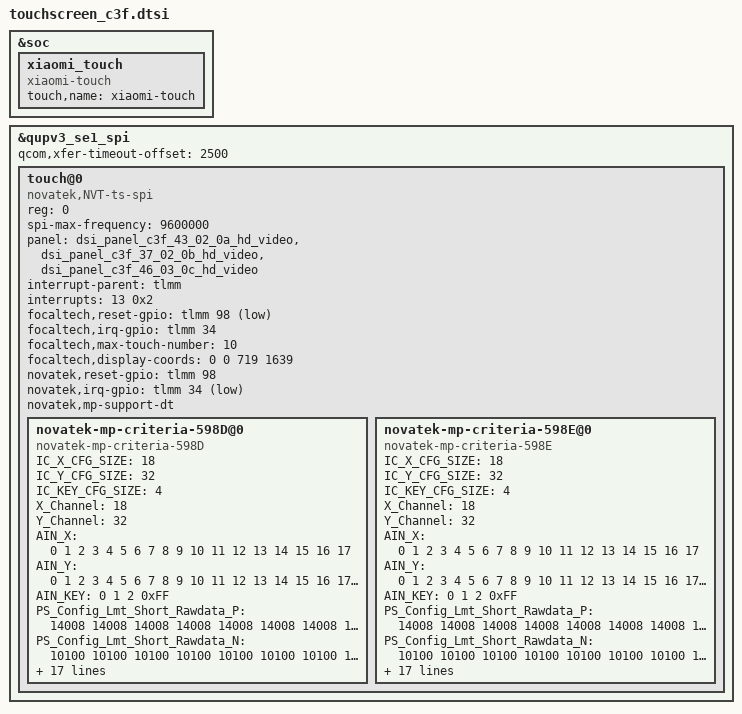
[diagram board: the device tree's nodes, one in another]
/*
 * Copyright (C) 2024 Novatek, Inc.
 *
 * $Revision$
 * $Date$
 *
 * This program is free software; you can redistribute it and/or modify
 * it under the terms of the GNU General Public License as published by
 * the Free Software Foundation; either version 2 of the License, or
 * (at your option) any later version.
 *
 * This program is distributed in the hope that it will be useful, but WITHOUT
 * ANY WARRANTY; without even the implied warranty of MERCHANTABILITY or
 * FITNESS FOR A PARTICULAR PURPOSE.  See the GNU General Public License for
 * more details.
 *
 */
&soc {
    xiaomi_touch {
        status = "okay";
        compatible = "xiaomi-touch";
        touch,name = "xiaomi-touch";
    };
};

&qupv3_se1_spi {
    status = "ok";
    qcom,xfer-timeout-offset = <2500>;

    touch@0 {
        compatible = "novatek,NVT-ts-spi","focaltech,fts";
        reg = <0>; //Same as CS ID
        status = "ok";

        spi-max-frequency = <9600000>;    //4800000,9600000,15000000,19200000
        panel = <&dsi_panel_c3f_43_02_0a_hd_video &dsi_panel_c3f_37_02_0b_hd_video &dsi_panel_c3f_46_03_0c_hd_video>;

        /*************** Focaltech FT8057M device tree ***************/
        interrupt-parent = <&tlmm>;
        interrupts = <13 0x2>;
        focaltech,reset-gpio = <&tlmm 98 0x01>;
        focaltech,irq-gpio = <&tlmm 34 0x02>;
        focaltech,max-touch-number = <10>;
        focaltech,display-coords =  <0 0 719 1639>;

        /*************** Novatek NT36528 device tree ***************/
        novatek,reset-gpio = <&tlmm 98 0x00>;
        novatek,irq-gpio = <&tlmm 34 0x2001>;

        //novatek,pen-support;
        //novatek,spi-rd-fast-addr = <0x03F310>;

        /* MP */
        novatek,mp-support-dt;

        /* for Xiaomi C3F NT36528A Truly 6.88" panel module */
        novatek-mp-criteria-598D@0 {
            #address-cells = <1>;
            #size-cells = <0>;
            compatible = "novatek-mp-criteria-598D";

            /* MP Config */
            IC_X_CFG_SIZE = <18>;
            IC_Y_CFG_SIZE = <32>;
            IC_KEY_CFG_SIZE = <4>;
            X_Channel = <18>;
            Y_Channel = <32>;
            AIN_X = <0 1 2 3 4 5 6 7 8 9 10 11 12 13 14 15 16 17>;
            AIN_Y = <0 1 2 3 4 5 6 7 8 9 10 11 12 13 14 15 16 17 18 19 20 21 22 23 24 25 26 27 28 29 30 31>;
            AIN_KEY = <0 1 2 0xFF>;

            /* MP Criteria */
            PS_Config_Lmt_Short_Rawdata_P = <
                14008 14008 14008 14008 14008 14008 14008 14008 14008 14008 14008 14008 14008 14008 14008 14008 14008 14008
                14008 14008 14008 14008 14008 14008 14008 14008 14008 14008 14008 14008 14008 14008 14008 14008 14008 14008
                14008 14008 14008 14008 14008 14008 14008 14008 14008 14008 14008 14008 14008 14008 14008 14008 14008 14008
                14008 14008 14008 14008 14008 14008 14008 14008 14008 14008 14008 14008 14008 14008 14008 14008 14008 14008
                14008 14008 14008 14008 14008 14008 14008 14008 14008 14008 14008 14008 14008 14008 14008 14008 14008 14008
                14008 14008 14008 14008 14008 14008 14008 14008 14008 14008 14008 14008 14008 14008 14008 14008 14008 14008
                14008 14008 14008 14008 14008 14008 14008 14008 14008 14008 14008 14008 14008 14008 14008 14008 14008 14008
                14008 14008 14008 14008 14008 14008 14008 14008 14008 14008 14008 14008 14008 14008 14008 14008 14008 14008
                14008 14008 14008 14008 14008 14008 14008 14008 14008 14008 14008 14008 14008 14008 14008 14008 14008 14008
                14008 14008 14008 14008 14008 14008 14008 14008 14008 14008 14008 14008 14008 14008 14008 14008 14008 14008
                14008 14008 14008 14008 14008 14008 14008 14008 14008 14008 14008 14008 14008 14008 14008 14008 14008 14008
                14008 14008 14008 14008 14008 14008 14008 14008 14008 14008 14008 14008 14008 14008 14008 14008 14008 14008
                14008 14008 14008 14008 14008 14008 14008 14008 14008 14008 14008 14008 14008 14008 14008 14008 14008 14008
                14008 14008 14008 14008 14008 14008 14008 14008 14008 14008 14008 14008 14008 14008 14008 14008 14008 14008
                14008 14008 14008 14008 14008 14008 14008 14008 14008 14008 14008 14008 14008 14008 14008 14008 14008 14008
                14008 14008 14008 14008 14008 14008 14008 14008 14008 14008 14008 14008 14008 14008 14008 14008 14008 14008
                14008 14008 14008 14008 14008 14008 14008 14008 14008 14008 14008 14008 14008 14008 14008 14008 14008 14008
                14008 14008 14008 14008 14008 14008 14008 14008 14008 14008 14008 14008 14008 14008 14008 14008 14008 14008
                14008 14008 14008 14008 14008 14008 14008 14008 14008 14008 14008 14008 14008 14008 14008 14008 14008 14008
                14008 14008 14008 14008 14008 14008 14008 14008 14008 14008 14008 14008 14008 14008 14008 14008 14008 14008
                14008 14008 14008 14008 14008 14008 14008 14008 14008 14008 14008 14008 14008 14008 14008 14008 14008 14008
                14008 14008 14008 14008 14008 14008 14008 14008 14008 14008 14008 14008 14008 14008 14008 14008 14008 14008
                14008 14008 14008 14008 14008 14008 14008 14008 14008 14008 14008 14008 14008 14008 14008 14008 14008 14008
                14008 14008 14008 14008 14008 14008 14008 14008 14008 14008 14008 14008 14008 14008 14008 14008 14008 14008
                14008 14008 14008 14008 14008 14008 14008 14008 14008 14008 14008 14008 14008 14008 14008 14008 14008 14008
                14008 14008 14008 14008 14008 14008 14008 14008 14008 14008 14008 14008 14008 14008 14008 14008 14008 14008
                14008 14008 14008 14008 14008 14008 14008 14008 14008 14008 14008 14008 14008 14008 14008 14008 14008 14008
                14008 14008 14008 14008 14008 14008 14008 14008 14008 14008 14008 14008 14008 14008 14008 14008 14008 14008
                14008 14008 14008 14008 14008 14008 14008 14008 14008 14008 14008 14008 14008 14008 14008 14008 14008 14008
                14008 14008 14008 14008 14008 14008 14008 14008 14008 14008 14008 14008 14008 14008 14008 14008 14008 14008
                14008 14008 14008 14008 14008 14008 14008 14008 14008 14008 14008 14008 14008 14008 14008 14008 14008 14008
                14008 14008 14008 14008 14008 14008 14008 14008 14008 14008 14008 14008 14008 14008 14008 14008 14008 14008
                14008 14008 14008>;

            PS_Config_Lmt_Short_Rawdata_N = <
                10100 10100 10100 10100 10100 10100 10100 10100 10100 10100 10100 10100 10100 10100 10100 10100 10100 10100
                10100 10100 10100 10100 10100 10100 10100 10100 10100 10100 10100 10100 10100 10100 10100 10100 10100 10100
                10100 10100 10100 10100 10100 10100 10100 10100 10100 10100 10100 10100 10100 10100 10100 10100 10100 10100
                10100 10100 10100 10100 10100 10100 10100 10100 10100 10100 10100 10100 10100 10100 10100 10100 10100 10100
                10100 10100 10100 10100 10100 10100 10100 10100 10100 10100 10100 10100 10100 10100 10100 10100 10100 10100
                10100 10100 10100 10100 10100 10100 10100 10100 10100 10100 10100 10100 10100 10100 10100 10100 10100 10100
                10100 10100 10100 10100 10100 10100 10100 10100 10100 10100 10100 10100 10100 10100 10100 10100 10100 10100
                10100 10100 10100 10100 10100 10100 10100 10100 10100 10100 10100 10100 10100 10100 10100 10100 10100 10100
                10100 10100 10100 10100 10100 10100 10100 10100 10100 10100 10100 10100 10100 10100 10100 10100 10100 10100
                10100 10100 10100 10100 10100 10100 10100 10100 10100 10100 10100 10100 10100 10100 10100 10100 10100 10100
                10100 10100 10100 10100 10100 10100 10100 10100 10100 10100 10100 10100 10100 10100 10100 10100 10100 10100
                10100 10100 10100 10100 10100 10100 10100 10100 10100 10100 10100 10100 10100 10100 10100 10100 10100 10100
                10100 10100 10100 10100 10100 10100 10100 10100 10100 10100 10100 10100 10100 10100 10100 10100 10100 10100
                10100 10100 10100 10100 10100 10100 10100 10100 10100 10100 10100 10100 10100 10100 10100 10100 10100 10100
                10100 10100 10100 10100 10100 10100 10100 10100 10100 10100 10100 10100 10100 10100 10100 10100 10100 10100
                10100 10100 10100 10100 10100 10100 10100 10100 10100 10100 10100 10100 10100 10100 10100 10100 10100 10100
                10100 10100 10100 10100 10100 10100 10100 10100 10100 10100 10100 10100 10100 10100 10100 10100 10100 10100
                10100 10100 10100 10100 10100 10100 10100 10100 10100 10100 10100 10100 10100 10100 10100 10100 10100 10100
                10100 10100 10100 10100 10100 10100 10100 10100 10100 10100 10100 10100 10100 10100 10100 10100 10100 10100
                10100 10100 10100 10100 10100 10100 10100 10100 10100 10100 10100 10100 10100 10100 10100 10100 10100 10100
                10100 10100 10100 10100 10100 10100 10100 10100 10100 10100 10100 10100 10100 10100 10100 10100 10100 10100
                10100 10100 10100 10100 10100 10100 10100 10100 10100 10100 10100 10100 10100 10100 10100 10100 10100 10100
                10100 10100 10100 10100 10100 10100 10100 10100 10100 10100 10100 10100 10100 10100 10100 10100 10100 10100
                10100 10100 10100 10100 10100 10100 10100 10100 10100 10100 10100 10100 10100 10100 10100 10100 10100 10100
                10100 10100 10100 10100 10100 10100 10100 10100 10100 10100 10100 10100 10100 10100 10100 10100 10100 10100
                10100 10100 10100 10100 10100 10100 10100 10100 10100 10100 10100 10100 10100 10100 10100 10100 10100 10100
                10100 10100 10100 10100 10100 10100 10100 10100 10100 10100 10100 10100 10100 10100 10100 10100 10100 10100
                10100 10100 10100 10100 10100 10100 10100 10100 10100 10100 10100 10100 10100 10100 10100 10100 10100 10100
                10100 10100 10100 10100 10100 10100 10100 10100 10100 10100 10100 10100 10100 10100 10100 10100 10100 10100
                10100 10100 10100 10100 10100 10100 10100 10100 10100 10100 10100 10100 10100 10100 10100 10100 10100 10100
                10100 10100 10100 10100 10100 10100 10100 10100 10100 10100 10100 10100 10100 10100 10100 10100 10100 10100
                10100 10100 10100 10100 10100 10100 10100 10100 10100 10100 10100 10100 10100 10100 10100 10100 10100 10100
                10000 10000 10000>;

            PS_Config_Lmt_Open_Rawdata_P = <
                2594 2575 2547 2524 2500 2492 2503 2444 65535 65535 2391 2437 2428 2422 2418 2421 2443 2514
                2673 2667 2647 2643 2631 2617 2615 2597 2580 2456 2471 2479 2477 2474 2463 2453 2468 2533
                2712 2712 2694 2688 2680 2664 2657 2638 2621 2509 2523 2531 2530 2524 2510 2496 2510 2573
                2661 2675 2654 2649 2638 2626 2619 2601 2580 2533 2549 2559 2556 2547 2535 2526 2540 2603
                2727 2754 2737 2729 2723 2709 2701 2688 2664 2561 2570 2580 2576 2580 2563 2547 2561 2617
                2808 2843 2824 2817 2810 2796 2792 2772 2754 2583 2598 2611 2611 2608 2594 2582 2601 2653
                2757 2701 2654 2646 2628 2610 2617 2603 2590 2654 2663 2667 2654 2652 2653 2649 2692 2650
                2797 2730 2688 2675 2657 2642 2652 2640 2626 2705 2717 2716 2702 2702 2702 2701 2737 2709
                2849 2778 2740 2724 2710 2698 2712 2699 2682 2734 2738 2747 2726 2723 2717 2713 2750 2738
                2888 2815 2778 2762 2741 2733 2745 2734 2722 2743 2752 2762 2747 2743 2740 2734 2769 2769
                2919 2846 2806 2793 2776 2766 2779 2766 2751 2862 2874 2870 2856 2853 2850 2849 2888 2892
                2971 2894 2856 2845 2821 2815 2827 2813 2797 2871 2883 2885 2866 2864 2860 2853 2891 2909
                3024 2947 2909 2899 2877 2867 2887 2869 2859 2887 2905 2899 2880 2870 2862 2855 2895 2926
                3066 2988 2947 2939 2922 2913 2922 2909 2894 2902 2920 2922 2909 2908 2897 2890 2922 2958
                3112 3032 2992 2982 2972 2962 2975 2962 2941 3020 3034 3044 3024 3020 3014 3000 3032 3083
                3184 3107 3073 3060 3045 3035 3042 3031 3010 2999 3013 3017 3003 2996 2993 2986 3020 3077
                3259 3175 3139 3129 3115 3098 3109 3097 3079 3088 3098 3104 3090 3093 3081 3065 3097 3172
                3266 3185 3156 3143 3128 3119 3128 3107 3088 3077 3087 3097 3077 3073 3072 3063 3091 3163
                3315 3238 3206 3200 3181 3171 3182 3160 3147 3142 3158 3160 3157 3147 3139 3132 3161 3234
                3340 3261 3230 3224 3212 3202 3213 3196 3174 3158 3178 3178 3167 3157 3153 3147 3178 3259
                3461 3387 3352 3349 3335 3325 3333 3318 3293 3221 3242 3252 3242 3228 3223 3209 3240 3321
                3499 3422 3389 3380 3368 3356 3364 3346 3318 3290 3312 3319 3314 3314 3307 3297 3321 3401
                3541 3459 3429 3420 3412 3402 3408 3395 3366 3354 3374 3385 3377 3377 3374 3360 3385 3464
                3587 3506 3479 3465 3457 3447 3444 3429 3401 3381 3401 3408 3398 3395 3385 3374 3401 3475
                3737 3655 3629 3619 3597 3585 3592 3577 3550 3508 3534 3539 3528 3524 3514 3506 3529 3611
                3686 3618 3592 3581 3562 3553 3556 3535 3507 3508 3532 3542 3535 3541 3536 3528 3549 3625
                3762 3692 3662 3655 3646 3632 3634 3612 3584 3550 3580 3584 3574 3566 3555 3545 3569 3644
                3800 3728 3703 3696 3679 3674 3678 3655 3630 3564 3588 3601 3592 3590 3588 3576 3592 3671
                3697 3828 3801 3797 3786 3776 3773 3752 3723 3651 3679 3692 3679 3681 3678 3661 3681 3583
                3742 3863 3844 3832 3816 3802 3797 3772 3742 3676 3702 3713 3710 3716 3710 3699 3711 3632
                3794 3947 3923 3912 3891 3881 3881 3863 3830 3721 3745 3753 3748 3753 3742 3738 3758 3654
                3802 3966 3976 3962 3940 3917 3913 3896 3872 3742 3765 3774 3774 3776 3772 3767 3753 3643
                5120 5120 5120>;

            PS_Config_Lmt_Open_Rawdata_N = <
                1112 1103 1091 1082 1072 1068 1073 1048 (-65535) (-65535) 1025 1045 1040 1038 1036 1037 1047 1078
                1145 1143 1135 1133 1127 1121 1121 1113 1106 1052 1059 1063 1061 1060 1055 1051 1058 1085
                1162 1162 1154 1152 1148 1142 1139 1130 1123 1075 1081 1085 1084 1082 1076 1070 1076 1103
                1141 1147 1138 1135 1130 1126 1123 1115 1106 1085 1093 1097 1096 1091 1087 1082 1088 1115
                1169 1180 1173 1169 1167 1161 1157 1152 1142 1097 1102 1106 1104 1106 1099 1091 1097 1121
                1204 1219 1210 1207 1204 1198 1196 1188 1180 1107 1114 1119 1119 1118 1112 1106 1115 1137
                1181 1157 1138 1134 1126 1118 1121 1115 1110 1138 1141 1143 1138 1136 1137 1135 1154 1136
                1199 1170 1152 1147 1139 1132 1136 1132 1126 1159 1165 1164 1158 1158 1158 1157 1173 1161
                1221 1190 1174 1168 1162 1156 1162 1157 1150 1172 1174 1177 1168 1167 1165 1163 1178 1174
                1238 1207 1190 1184 1175 1171 1177 1172 1166 1175 1180 1184 1177 1175 1174 1172 1187 1187
                1251 1220 1202 1197 1190 1186 1191 1186 1179 1226 1232 1230 1224 1223 1222 1221 1238 1240
                1273 1240 1224 1219 1209 1207 1211 1205 1199 1231 1235 1237 1228 1228 1226 1223 1239 1247
                1296 1263 1247 1243 1233 1229 1237 1229 1225 1237 1245 1243 1234 1230 1226 1223 1241 1254
                1314 1280 1263 1259 1252 1249 1252 1247 1240 1244 1252 1252 1247 1246 1241 1238 1252 1268
                1334 1300 1282 1278 1274 1270 1275 1270 1261 1294 1300 1304 1296 1294 1292 1286 1300 1321
                1364 1331 1317 1312 1305 1301 1304 1299 1290 1285 1291 1293 1287 1284 1283 1280 1294 1319
                1397 1361 1345 1341 1335 1328 1333 1327 1319 1324 1328 1330 1324 1325 1321 1313 1327 1360
                1400 1365 1352 1347 1340 1337 1340 1331 1324 1319 1323 1327 1319 1317 1316 1313 1325 1355
                1421 1388 1374 1372 1363 1359 1364 1354 1349 1346 1354 1354 1353 1349 1345 1342 1355 1386
                1432 1397 1384 1382 1376 1372 1377 1370 1360 1354 1362 1362 1357 1353 1351 1349 1362 1397
                1483 1451 1436 1435 1429 1425 1429 1422 1411 1381 1390 1394 1390 1384 1381 1375 1388 1423
                1499 1466 1453 1448 1444 1438 1442 1434 1422 1410 1420 1423 1420 1420 1417 1413 1423 1457
                1517 1483 1469 1466 1462 1458 1460 1455 1442 1438 1446 1451 1447 1447 1446 1440 1451 1484
                1537 1502 1491 1485 1481 1477 1476 1469 1457 1449 1457 1460 1456 1455 1451 1446 1457 1489
                1601 1567 1555 1551 1541 1537 1540 1533 1522 1504 1514 1517 1512 1510 1506 1502 1513 1547
                1580 1550 1540 1535 1526 1523 1524 1515 1503 1504 1514 1518 1515 1517 1516 1512 1521 1553
                1612 1582 1570 1567 1562 1556 1558 1548 1536 1522 1534 1536 1532 1528 1523 1519 1529 1562
                1628 1598 1587 1584 1577 1574 1576 1567 1556 1528 1538 1543 1540 1538 1538 1532 1540 1573
                1585 1640 1629 1627 1622 1618 1617 1608 1595 1565 1577 1582 1577 1577 1576 1569 1577 1535
                1604 1655 1648 1642 1636 1630 1627 1616 1604 1576 1586 1591 1590 1592 1590 1585 1591 1556
                1626 1691 1681 1676 1667 1663 1663 1655 1642 1595 1605 1609 1606 1609 1604 1602 1610 1566
                1630 1700 1704 1698 1688 1679 1677 1670 1660 1604 1613 1618 1618 1618 1616 1615 1609 1561
                (-511) (-511) (-511)>;

            PS_Config_Lmt_FW_Rawdata_P = <
                1124 1102 1133 1105 1096 1110 1131 1114 65535 65535 1112 1121 1119 1109 1106 1124 1126 1113
                1117 1110 1119 1117 1113 1114 1113 1112 1133 1130 1124 1126 1131 1128 1127 1114 1117 1123
                1133 1103 1102 1135 1137 1130 1126 1123 1130 1121 1127 1121 1119 1123 1119 1116 1119 1127
                1135 1102 1114 1127 1123 1126 1124 1127 1120 1113 1134 1137 1134 1131 1130 1113 1126 1109
                1117 1116 1121 1109 1100 1106 1105 1109 1123 1121 1116 1114 1114 1110 1105 1130 1119 1120
                1130 1112 1128 1114 1113 1113 1103 1102 1135 1107 1123 1120 1120 1126 1121 1116 1112 1120
                1119 1116 1119 1121 1112 1116 1114 1102 1100 1113 1114 1109 1112 1109 1102 1131 1131 1138
                1137 1116 1127 1126 1124 1126 1135 1128 1123 1121 1120 1114 1121 1123 1113 1113 1123 1117
                1134 1121 1130 1135 1128 1134 1131 1127 1123 1123 1135 1135 1134 1133 1131 1127 1135 1114
                1116 1124 1124 1117 1119 1113 1128 1131 1138 1116 1130 1138 1126 1128 1126 1121 1127 1121
                1127 1121 1121 1114 1107 1113 1113 1114 1123 1134 1135 1126 1109 1107 1100 1116 1133 1103
                1154 1103 1148 1141 1137 1134 1135 1134 1124 1114 1109 1130 1134 1126 1128 1128 1128 1117
                1112 1116 1126 1130 1126 1114 1109 1114 1121 1107 1103 1119 1126 1123 1121 1116 1116 1096
                1117 1113 1113 1113 1105 1107 1103 1109 1121 1131 1127 1112 1113 1126 1121 1123 1128 1123
                1107 1133 1109 1109 1116 1124 1117 1106 1106 1117 1127 1117 1116 1123 1120 1121 1113 1114
                1126 1121 1128 1131 1126 1134 1137 1123 1103 1107 1130 1131 1127 1124 1120 1114 1133 1117
                1113 1117 1120 1121 1127 1113 1112 1124 1131 1106 1116 1119 1116 1114 1117 1120 1120 1120
                1137 1124 1120 1112 1120 1120 1114 1114 1109 1096 1124 1138 1135 1145 1142 1116 1134 1117
                1127 1123 1112 1120 1127 1121 1126 1135 1121 1124 1130 1120 1119 1116 1120 1105 1141 1121
                1107 1117 1114 1127 1123 1123 1123 1133 1134 1121 1120 1116 1119 1114 1106 1107 1110 1109
                1127 1128 1114 1114 1117 1123 1131 1123 1110 1126 1110 1112 1106 1105 1112 1114 1110 1113
                1110 1121 1113 1127 1113 1106 1112 1112 1128 1128 1126 1128 1134 1134 1124 1102 1102 1098
                1119 1103 1135 1131 1131 1131 1134 1133 1123 1114 1128 1127 1120 1117 1120 1128 1109 1106
                1114 1102 1135 1103 1103 1102 1107 1105 1121 1100 1128 1119 1130 1130 1121 1126 1121 1127
                1103 1119 1107 1105 1117 1117 1120 1124 1106 1124 1126 1120 1126 1121 1124 1120 1126 1119
                1113 1124 1128 1110 1114 1116 1113 1112 1126 1131 1100 1103 1102 1105 1105 1105 1114 1082
                1119 1112 1120 1113 1112 1100 1105 1100 1130 1121 1131 1134 1128 1137 1137 1119 1128 1112
                1110 1144 1112 1123 1114 1110 1105 1105 1141 1137 1120 1114 1116 1119 1113 1110 1112 1096
                1114 1133 1117 1131 1131 1120 1116 1117 1130 1126 1120 1123 1127 1121 1127 1114 1137 1110
                1127 1117 1124 1116 1120 1121 1131 1130 1120 1120 1116 1126 1123 1127 1124 1120 1130 1130
                1113 1113 1121 1112 1120 1127 1130 1134 1127 1093 1148 1135 1133 1128 1116 1135 1130 1121
                1107 1127 1112 1123 1113 1112 1107 1109 1127 1112 1120 1109 1110 1116 1112 1117 1109 1116
                3840 3840 3840>;

            PS_Config_Lmt_FW_Rawdata_N = <
                482 472 485 473 470 476 485 478 (-65535) (-65535) 476 481 479 475 474 482 482 477
                479 476 479 479 477 478 477 476 485 484 482 482 485 484 483 478 479 481
                485 473 472 487 487 484 482 481 484 481 483 481 479 481 479 478 479 483
                487 472 478 483 481 482 482 483 480 477 486 487 486 485 484 477 482 475
                479 478 481 475 472 474 473 475 481 481 478 478 478 476 473 484 479 480
                484 476 484 478 477 477 473 472 487 475 481 480 480 482 481 478 476 480
                479 478 479 481 476 478 478 472 472 477 478 475 476 475 472 485 485 488
                487 478 483 482 482 482 487 484 481 481 480 478 481 481 477 477 481 479
                486 481 484 487 484 486 485 483 481 481 487 487 486 485 485 483 487 478
                478 482 482 479 479 477 484 485 488 478 484 488 482 484 482 481 483 481
                483 481 481 478 475 477 477 478 481 486 487 482 475 475 472 478 485 473
                494 473 492 489 487 486 487 486 482 478 475 484 486 482 484 484 484 479
                476 478 482 484 482 478 475 478 481 475 473 479 482 481 481 478 478 470
                479 477 477 477 473 475 473 475 481 485 483 476 477 482 481 481 484 481
                475 485 475 475 478 482 479 474 474 479 483 479 478 481 480 481 477 478
                482 481 484 485 482 486 487 481 473 475 484 485 483 482 480 478 485 479
                477 479 480 481 483 477 476 482 485 474 478 479 478 478 479 480 480 480
                487 482 480 476 480 480 478 478 475 470 482 488 487 491 490 478 486 479
                483 481 476 480 483 481 482 487 481 482 484 480 479 478 480 473 489 481
                475 479 478 483 481 481 481 485 486 481 480 478 479 478 474 475 476 475
                483 484 478 478 479 481 485 481 476 482 476 476 474 473 476 478 476 477
                476 481 477 483 477 474 476 476 484 484 482 484 486 486 482 472 472 470
                479 473 487 485 485 485 486 485 481 478 484 483 480 479 480 484 475 474
                478 472 487 473 473 472 475 473 481 472 484 479 484 484 481 482 481 483
                473 479 475 473 479 479 480 482 474 482 482 480 482 481 482 480 482 479
                477 482 484 476 478 478 477 476 482 485 472 473 472 473 473 473 478 464
                479 476 480 477 476 472 473 472 484 481 485 486 484 487 487 479 484 476
                476 490 476 481 478 476 473 473 489 487 480 478 478 479 477 476 476 470
                478 485 479 485 485 480 478 479 484 482 480 481 483 481 483 478 487 476
                483 479 482 478 480 481 485 484 480 480 478 482 481 483 482 480 484 484
                477 477 481 476 480 483 484 486 483 469 492 487 485 484 478 487 484 481
                475 483 476 481 477 476 475 475 483 476 480 475 476 478 476 479 475 478
                240 240 240>;

            PS_Config_Lmt_FW_CC_P = <
                47 46 43 43 43 43 43 43 65535 65535 43 43 43 43 43 43 44 47
                50 47 46 46 46 46 44 44 46 46 44 44 44 44 44 46 47 50
                50 48 47 46 46 46 46 46 46 46 46 46 46 46 46 46 47 50
                50 48 46 46 46 46 46 46 46 46 46 46 46 46 46 46 47 50
                50 48 47 46 46 46 46 46 47 46 46 46 46 46 46 46 48 50
                50 48 47 46 46 46 46 46 47 46 46 46 46 46 46 46 48 50
                51 48 47 46 46 46 46 46 46 46 46 46 46 46 46 47 48 50
                51 48 47 46 46 46 46 46 46 46 46 46 46 46 46 47 48 51
                51 48 47 46 46 46 46 46 46 46 46 46 46 46 46 47 48 51
                51 48 47 46 46 46 46 46 46 46 46 46 46 46 46 47 48 51
                51 50 47 46 46 46 46 46 47 47 46 46 46 46 46 47 48 51
                51 48 47 46 46 46 46 46 46 46 46 46 46 46 46 47 48 51
                51 50 47 46 46 46 46 46 47 47 47 47 46 46 46 47 50 51
                51 48 47 46 46 46 46 46 47 47 46 46 46 46 46 47 48 51
                52 50 47 46 46 46 47 47 47 47 47 47 46 46 46 47 50 51
                51 48 47 46 46 46 46 46 47 47 47 47 46 46 46 47 50 51
                52 50 48 47 47 47 47 47 47 47 47 47 47 47 47 47 50 52
                51 50 47 47 47 47 47 47 47 47 47 47 47 47 46 47 50 51
                52 50 48 47 47 47 47 47 47 47 47 47 47 47 47 48 50 52
                52 50 48 47 47 47 47 47 47 47 47 47 47 47 47 47 50 52
                52 50 48 47 47 47 47 47 47 47 47 47 47 47 47 48 50 52
                52 50 48 47 47 47 47 47 47 47 47 47 47 47 47 48 50 52
                52 51 48 48 48 47 48 48 48 48 47 47 47 47 47 48 50 52
                52 51 48 48 47 47 47 47 48 48 47 47 47 47 47 48 51 52
                54 51 50 48 48 48 48 48 48 48 48 48 48 48 47 48 51 52
                52 51 48 47 47 47 47 47 48 48 47 47 47 47 47 48 50 52
                54 51 48 48 48 48 48 48 48 48 48 48 48 48 48 48 51 54
                54 51 50 48 48 48 48 48 48 48 48 48 48 48 48 50 51 54
                52 51 50 48 48 48 48 48 48 48 48 48 48 48 48 48 51 52
                52 51 50 48 48 48 48 48 48 48 48 47 48 48 48 48 51 52
                52 51 48 48 48 47 47 47 48 48 47 47 47 47 48 48 51 52
                52 51 50 48 48 48 48 48 48 48 47 48 48 48 48 48 51 52
                314 314 314>;

            PS_Config_Lmt_FW_CC_N = <
                21 20 19 19 19 19 19 19 (-65535) (-65535) 19 19 19 19 19 19 20 21
                22 21 20 20 20 20 20 20 20 20 20 20 20 20 20 20 21 22
                22 22 21 20 20 20 20 20 20 20 20 20 20 20 20 20 21 22
                22 22 20 20 20 20 20 20 20 20 20 20 20 20 20 20 21 22
                22 22 21 20 20 20 20 20 21 20 20 20 20 20 20 20 22 22
                22 22 21 20 20 20 20 20 21 20 20 20 20 20 20 20 22 22
                23 22 21 20 20 20 20 20 20 20 20 20 20 20 20 21 22 22
                23 22 21 20 20 20 20 20 20 20 20 20 20 20 20 21 22 23
                23 22 21 20 20 20 20 20 20 20 20 20 20 20 20 21 22 23
                23 22 21 20 20 20 20 20 20 20 20 20 20 20 20 21 22 23
                23 22 21 20 20 20 20 20 21 21 20 20 20 20 20 21 22 23
                23 22 21 20 20 20 20 20 20 20 20 20 20 20 20 21 22 23
                23 22 21 20 20 20 20 20 21 21 21 21 20 20 20 21 22 23
                23 22 21 20 20 20 20 20 21 21 20 20 20 20 20 21 22 23
                24 22 21 20 20 20 21 21 21 21 21 21 20 20 20 21 22 23
                23 22 21 20 20 20 20 20 21 21 21 21 20 20 20 21 22 23
                24 22 22 21 21 21 21 21 21 21 21 21 21 21 21 21 22 24
                23 22 21 21 21 21 21 21 21 21 21 21 21 21 20 21 22 23
                24 22 22 21 21 21 21 21 21 21 21 21 21 21 21 22 22 24
                24 22 22 21 21 21 21 21 21 21 21 21 21 21 21 21 22 24
                24 22 22 21 21 21 21 21 21 21 21 21 21 21 21 22 22 24
                24 22 22 21 21 21 21 21 21 21 21 21 21 21 21 22 22 24
                24 23 22 22 22 21 22 22 22 22 21 21 21 21 21 22 22 24
                24 23 22 22 21 21 21 21 22 22 21 21 21 21 21 22 23 24
                24 23 22 22 22 22 22 22 22 22 22 22 22 22 21 22 23 24
                24 23 22 21 21 21 21 21 22 22 21 21 21 21 21 22 22 24
                24 23 22 22 22 22 22 22 22 22 22 22 22 22 22 22 23 24
                24 23 22 22 22 22 22 22 22 22 22 22 22 22 22 22 23 24
                24 23 22 22 22 22 22 22 22 22 22 22 22 22 22 22 23 24
                24 23 22 22 22 22 22 22 22 22 22 21 22 22 22 22 23 24
                24 23 22 22 22 21 21 21 22 22 21 21 21 21 22 22 23 24
                24 23 22 22 22 22 22 22 22 22 21 22 22 22 22 22 23 24
                0 0 0>;

            PS_Config_Lmt_FW_Diff_P = <
                50 50 50 50 50 50 50 50 65535 65535 50 50 50 50 50 50 50 50
                50 50 50 50 50 50 50 50 50 50 50 50 50 50 50 50 50 50
                50 50 50 50 50 50 50 50 50 50 50 50 50 50 50 50 50 50
                50 50 50 50 50 50 50 50 50 50 50 50 50 50 50 50 50 50
                50 50 50 50 50 50 50 50 50 50 50 50 50 50 50 50 50 50
                50 50 50 50 50 50 50 50 50 50 50 50 50 50 50 50 50 50
                50 50 50 50 50 50 50 50 50 50 50 50 50 50 50 50 50 50
                50 50 50 50 50 50 50 50 50 50 50 50 50 50 50 50 50 50
                50 50 50 50 50 50 50 50 50 50 50 50 50 50 50 50 50 50
                50 50 50 50 50 50 50 50 50 50 50 50 50 50 50 50 50 50
                50 50 50 50 50 50 50 50 50 50 50 50 50 50 50 50 50 50
                50 50 50 50 50 50 50 50 50 50 50 50 50 50 50 50 50 50
                50 50 50 50 50 50 50 50 50 50 50 50 50 50 50 50 50 50
                50 50 50 50 50 50 50 50 50 50 50 50 50 50 50 50 50 50
                50 50 50 50 50 50 50 50 50 50 50 50 50 50 50 50 50 50
                50 50 50 50 50 50 50 50 50 50 50 50 50 50 50 50 50 50
                50 50 50 50 50 50 50 50 50 50 50 50 50 50 50 50 50 50
                50 50 50 50 50 50 50 50 50 50 50 50 50 50 50 50 50 50
                50 50 50 50 50 50 50 50 50 50 50 50 50 50 50 50 50 50
                50 50 50 50 50 50 50 50 50 50 50 50 50 50 50 50 50 50
                50 50 50 50 50 50 50 50 50 50 50 50 50 50 50 50 50 50
                50 50 50 50 50 50 50 50 50 50 50 50 50 50 50 50 50 50
                50 50 50 50 50 50 50 50 50 50 50 50 50 50 50 50 50 50
                50 50 50 50 50 50 50 50 50 50 50 50 50 50 50 50 50 50
                50 50 50 50 50 50 50 50 50 50 50 50 50 50 50 50 50 50
                50 50 50 50 50 50 50 50 50 50 50 50 50 50 50 50 50 50
                50 50 50 50 50 50 50 50 50 50 50 50 50 50 50 50 50 50
                50 50 50 50 50 50 50 50 50 50 50 50 50 50 50 50 50 50
                50 50 50 50 50 50 50 50 50 50 50 50 50 50 50 50 50 50
                50 50 50 50 50 50 50 50 50 50 50 50 50 50 50 50 50 50
                50 50 50 50 50 50 50 50 50 50 50 50 50 50 50 50 50 50
                50 50 50 50 50 50 50 50 50 50 50 50 50 50 50 50 50 50
                75 75 75>;

            PS_Config_Lmt_FW_Diff_N = <
                (-50) (-50) (-50) (-50) (-50) (-50) (-50) (-50) (-65535) (-65535) (-50) (-50) (-50) (-50) (-50) (-50) (-50) (-50)
                (-50) (-50) (-50) (-50) (-50) (-50) (-50) (-50) (-50) (-50) (-50) (-50) (-50) (-50) (-50) (-50) (-50) (-50)
                (-50) (-50) (-50) (-50) (-50) (-50) (-50) (-50) (-50) (-50) (-50) (-50) (-50) (-50) (-50) (-50) (-50) (-50)
                (-50) (-50) (-50) (-50) (-50) (-50) (-50) (-50) (-50) (-50) (-50) (-50) (-50) (-50) (-50) (-50) (-50) (-50)
                (-50) (-50) (-50) (-50) (-50) (-50) (-50) (-50) (-50) (-50) (-50) (-50) (-50) (-50) (-50) (-50) (-50) (-50)
                (-50) (-50) (-50) (-50) (-50) (-50) (-50) (-50) (-50) (-50) (-50) (-50) (-50) (-50) (-50) (-50) (-50) (-50)
                (-50) (-50) (-50) (-50) (-50) (-50) (-50) (-50) (-50) (-50) (-50) (-50) (-50) (-50) (-50) (-50) (-50) (-50)
                (-50) (-50) (-50) (-50) (-50) (-50) (-50) (-50) (-50) (-50) (-50) (-50) (-50) (-50) (-50) (-50) (-50) (-50)
                (-50) (-50) (-50) (-50) (-50) (-50) (-50) (-50) (-50) (-50) (-50) (-50) (-50) (-50) (-50) (-50) (-50) (-50)
                (-50) (-50) (-50) (-50) (-50) (-50) (-50) (-50) (-50) (-50) (-50) (-50) (-50) (-50) (-50) (-50) (-50) (-50)
                (-50) (-50) (-50) (-50) (-50) (-50) (-50) (-50) (-50) (-50) (-50) (-50) (-50) (-50) (-50) (-50) (-50) (-50)
                (-50) (-50) (-50) (-50) (-50) (-50) (-50) (-50) (-50) (-50) (-50) (-50) (-50) (-50) (-50) (-50) (-50) (-50)
                (-50) (-50) (-50) (-50) (-50) (-50) (-50) (-50) (-50) (-50) (-50) (-50) (-50) (-50) (-50) (-50) (-50) (-50)
                (-50) (-50) (-50) (-50) (-50) (-50) (-50) (-50) (-50) (-50) (-50) (-50) (-50) (-50) (-50) (-50) (-50) (-50)
                (-50) (-50) (-50) (-50) (-50) (-50) (-50) (-50) (-50) (-50) (-50) (-50) (-50) (-50) (-50) (-50) (-50) (-50)
                (-50) (-50) (-50) (-50) (-50) (-50) (-50) (-50) (-50) (-50) (-50) (-50) (-50) (-50) (-50) (-50) (-50) (-50)
                (-50) (-50) (-50) (-50) (-50) (-50) (-50) (-50) (-50) (-50) (-50) (-50) (-50) (-50) (-50) (-50) (-50) (-50)
                (-50) (-50) (-50) (-50) (-50) (-50) (-50) (-50) (-50) (-50) (-50) (-50) (-50) (-50) (-50) (-50) (-50) (-50)
                (-50) (-50) (-50) (-50) (-50) (-50) (-50) (-50) (-50) (-50) (-50) (-50) (-50) (-50) (-50) (-50) (-50) (-50)
                (-50) (-50) (-50) (-50) (-50) (-50) (-50) (-50) (-50) (-50) (-50) (-50) (-50) (-50) (-50) (-50) (-50) (-50)
                (-50) (-50) (-50) (-50) (-50) (-50) (-50) (-50) (-50) (-50) (-50) (-50) (-50) (-50) (-50) (-50) (-50) (-50)
                (-50) (-50) (-50) (-50) (-50) (-50) (-50) (-50) (-50) (-50) (-50) (-50) (-50) (-50) (-50) (-50) (-50) (-50)
                (-50) (-50) (-50) (-50) (-50) (-50) (-50) (-50) (-50) (-50) (-50) (-50) (-50) (-50) (-50) (-50) (-50) (-50)
                (-50) (-50) (-50) (-50) (-50) (-50) (-50) (-50) (-50) (-50) (-50) (-50) (-50) (-50) (-50) (-50) (-50) (-50)
                (-50) (-50) (-50) (-50) (-50) (-50) (-50) (-50) (-50) (-50) (-50) (-50) (-50) (-50) (-50) (-50) (-50) (-50)
                (-50) (-50) (-50) (-50) (-50) (-50) (-50) (-50) (-50) (-50) (-50) (-50) (-50) (-50) (-50) (-50) (-50) (-50)
                (-50) (-50) (-50) (-50) (-50) (-50) (-50) (-50) (-50) (-50) (-50) (-50) (-50) (-50) (-50) (-50) (-50) (-50)
                (-50) (-50) (-50) (-50) (-50) (-50) (-50) (-50) (-50) (-50) (-50) (-50) (-50) (-50) (-50) (-50) (-50) (-50)
                (-50) (-50) (-50) (-50) (-50) (-50) (-50) (-50) (-50) (-50) (-50) (-50) (-50) (-50) (-50) (-50) (-50) (-50)
                (-50) (-50) (-50) (-50) (-50) (-50) (-50) (-50) (-50) (-50) (-50) (-50) (-50) (-50) (-50) (-50) (-50) (-50)
                (-50) (-50) (-50) (-50) (-50) (-50) (-50) (-50) (-50) (-50) (-50) (-50) (-50) (-50) (-50) (-50) (-50) (-50)
                (-50) (-50) (-50) (-50) (-50) (-50) (-50) (-50) (-50) (-50) (-50) (-50) (-50) (-50) (-50) (-50) (-50) (-50)
                (-75) (-75) (-75)>;

            PS_Config_Diff_Test_Frame = <50>;
        };

        /* for Xiaomi C3F NT36528A EBBG 6.88" panel module */
        novatek-mp-criteria-598E@0 {
            #address-cells = <1>;
            #size-cells = <0>;
            compatible = "novatek-mp-criteria-598E";

            /* MP Config */
            IC_X_CFG_SIZE = <18>;
            IC_Y_CFG_SIZE = <32>;
            IC_KEY_CFG_SIZE = <4>;
            X_Channel = <18>;
            Y_Channel = <32>;
            AIN_X = <0 1 2 3 4 5 6 7 8 9 10 11 12 13 14 15 16 17>;
            AIN_Y = <0 1 2 3 4 5 6 7 8 9 10 11 12 13 14 15 16 17 18 19 20 21 22 23 24 25 26 27 28 29 30 31>;
            AIN_KEY = <0 1 2 0xFF>;

            /* MP Criteria */
            PS_Config_Lmt_Short_Rawdata_P = <
                14008 14008 14008 14008 14008 14008 14008 14008 14008 14008 14008 14008 14008 14008 14008 14008 14008 14008
                14008 14008 14008 14008 14008 14008 14008 14008 14008 14008 14008 14008 14008 14008 14008 14008 14008 14008
                14008 14008 14008 14008 14008 14008 14008 14008 14008 14008 14008 14008 14008 14008 14008 14008 14008 14008
                14008 14008 14008 14008 14008 14008 14008 14008 14008 14008 14008 14008 14008 14008 14008 14008 14008 14008
                14008 14008 14008 14008 14008 14008 14008 14008 14008 14008 14008 14008 14008 14008 14008 14008 14008 14008
                14008 14008 14008 14008 14008 14008 14008 14008 14008 14008 14008 14008 14008 14008 14008 14008 14008 14008
                14008 14008 14008 14008 14008 14008 14008 14008 14008 14008 14008 14008 14008 14008 14008 14008 14008 14008
                14008 14008 14008 14008 14008 14008 14008 14008 14008 14008 14008 14008 14008 14008 14008 14008 14008 14008
                14008 14008 14008 14008 14008 14008 14008 14008 14008 14008 14008 14008 14008 14008 14008 14008 14008 14008
                14008 14008 14008 14008 14008 14008 14008 14008 14008 14008 14008 14008 14008 14008 14008 14008 14008 14008
                14008 14008 14008 14008 14008 14008 14008 14008 14008 14008 14008 14008 14008 14008 14008 14008 14008 14008
                14008 14008 14008 14008 14008 14008 14008 14008 14008 14008 14008 14008 14008 14008 14008 14008 14008 14008
                14008 14008 14008 14008 14008 14008 14008 14008 14008 14008 14008 14008 14008 14008 14008 14008 14008 14008
                14008 14008 14008 14008 14008 14008 14008 14008 14008 14008 14008 14008 14008 14008 14008 14008 14008 14008
                14008 14008 14008 14008 14008 14008 14008 14008 14008 14008 14008 14008 14008 14008 14008 14008 14008 14008
                14008 14008 14008 14008 14008 14008 14008 14008 14008 14008 14008 14008 14008 14008 14008 14008 14008 14008
                14008 14008 14008 14008 14008 14008 14008 14008 14008 14008 14008 14008 14008 14008 14008 14008 14008 14008
                14008 14008 14008 14008 14008 14008 14008 14008 14008 14008 14008 14008 14008 14008 14008 14008 14008 14008
                14008 14008 14008 14008 14008 14008 14008 14008 14008 14008 14008 14008 14008 14008 14008 14008 14008 14008
                14008 14008 14008 14008 14008 14008 14008 14008 14008 14008 14008 14008 14008 14008 14008 14008 14008 14008
                14008 14008 14008 14008 14008 14008 14008 14008 14008 14008 14008 14008 14008 14008 14008 14008 14008 14008
                14008 14008 14008 14008 14008 14008 14008 14008 14008 14008 14008 14008 14008 14008 14008 14008 14008 14008
                14008 14008 14008 14008 14008 14008 14008 14008 14008 14008 14008 14008 14008 14008 14008 14008 14008 14008
                14008 14008 14008 14008 14008 14008 14008 14008 14008 14008 14008 14008 14008 14008 14008 14008 14008 14008
                14008 14008 14008 14008 14008 14008 14008 14008 14008 14008 14008 14008 14008 14008 14008 14008 14008 14008
                14008 14008 14008 14008 14008 14008 14008 14008 14008 14008 14008 14008 14008 14008 14008 14008 14008 14008
                14008 14008 14008 14008 14008 14008 14008 14008 14008 14008 14008 14008 14008 14008 14008 14008 14008 14008
                14008 14008 14008 14008 14008 14008 14008 14008 14008 14008 14008 14008 14008 14008 14008 14008 14008 14008
                14008 14008 14008 14008 14008 14008 14008 14008 14008 14008 14008 14008 14008 14008 14008 14008 14008 14008
                14008 14008 14008 14008 14008 14008 14008 14008 14008 14008 14008 14008 14008 14008 14008 14008 14008 14008
                14008 14008 14008 14008 14008 14008 14008 14008 14008 14008 14008 14008 14008 14008 14008 14008 14008 14008
                14008 14008 14008 14008 14008 14008 14008 14008 14008 14008 14008 14008 14008 14008 14008 14008 14008 14008
                14008 14008 14008>;

            PS_Config_Lmt_Short_Rawdata_N = <
                10100 10100 10100 10100 10100 10100 10100 10100 10100 10100 10100 10100 10100 10100 10100 10100 10100 10100
                10100 10100 10100 10100 10100 10100 10100 10100 10100 10100 10100 10100 10100 10100 10100 10100 10100 10100
                10100 10100 10100 10100 10100 10100 10100 10100 10100 10100 10100 10100 10100 10100 10100 10100 10100 10100
                10100 10100 10100 10100 10100 10100 10100 10100 10100 10100 10100 10100 10100 10100 10100 10100 10100 10100
                10100 10100 10100 10100 10100 10100 10100 10100 10100 10100 10100 10100 10100 10100 10100 10100 10100 10100
                10100 10100 10100 10100 10100 10100 10100 10100 10100 10100 10100 10100 10100 10100 10100 10100 10100 10100
                10100 10100 10100 10100 10100 10100 10100 10100 10100 10100 10100 10100 10100 10100 10100 10100 10100 10100
                10100 10100 10100 10100 10100 10100 10100 10100 10100 10100 10100 10100 10100 10100 10100 10100 10100 10100
                10100 10100 10100 10100 10100 10100 10100 10100 10100 10100 10100 10100 10100 10100 10100 10100 10100 10100
                10100 10100 10100 10100 10100 10100 10100 10100 10100 10100 10100 10100 10100 10100 10100 10100 10100 10100
                10100 10100 10100 10100 10100 10100 10100 10100 10100 10100 10100 10100 10100 10100 10100 10100 10100 10100
                10100 10100 10100 10100 10100 10100 10100 10100 10100 10100 10100 10100 10100 10100 10100 10100 10100 10100
                10100 10100 10100 10100 10100 10100 10100 10100 10100 10100 10100 10100 10100 10100 10100 10100 10100 10100
                10100 10100 10100 10100 10100 10100 10100 10100 10100 10100 10100 10100 10100 10100 10100 10100 10100 10100
                10100 10100 10100 10100 10100 10100 10100 10100 10100 10100 10100 10100 10100 10100 10100 10100 10100 10100
                10100 10100 10100 10100 10100 10100 10100 10100 10100 10100 10100 10100 10100 10100 10100 10100 10100 10100
                10100 10100 10100 10100 10100 10100 10100 10100 10100 10100 10100 10100 10100 10100 10100 10100 10100 10100
                10100 10100 10100 10100 10100 10100 10100 10100 10100 10100 10100 10100 10100 10100 10100 10100 10100 10100
                10100 10100 10100 10100 10100 10100 10100 10100 10100 10100 10100 10100 10100 10100 10100 10100 10100 10100
                10100 10100 10100 10100 10100 10100 10100 10100 10100 10100 10100 10100 10100 10100 10100 10100 10100 10100
                10100 10100 10100 10100 10100 10100 10100 10100 10100 10100 10100 10100 10100 10100 10100 10100 10100 10100
                10100 10100 10100 10100 10100 10100 10100 10100 10100 10100 10100 10100 10100 10100 10100 10100 10100 10100
                10100 10100 10100 10100 10100 10100 10100 10100 10100 10100 10100 10100 10100 10100 10100 10100 10100 10100
                10100 10100 10100 10100 10100 10100 10100 10100 10100 10100 10100 10100 10100 10100 10100 10100 10100 10100
                10100 10100 10100 10100 10100 10100 10100 10100 10100 10100 10100 10100 10100 10100 10100 10100 10100 10100
                10100 10100 10100 10100 10100 10100 10100 10100 10100 10100 10100 10100 10100 10100 10100 10100 10100 10100
                10100 10100 10100 10100 10100 10100 10100 10100 10100 10100 10100 10100 10100 10100 10100 10100 10100 10100
                10100 10100 10100 10100 10100 10100 10100 10100 10100 10100 10100 10100 10100 10100 10100 10100 10100 10100
                10100 10100 10100 10100 10100 10100 10100 10100 10100 10100 10100 10100 10100 10100 10100 10100 10100 10100
                10100 10100 10100 10100 10100 10100 10100 10100 10100 10100 10100 10100 10100 10100 10100 10100 10100 10100
                10100 10100 10100 10100 10100 10100 10100 10100 10100 10100 10100 10100 10100 10100 10100 10100 10100 10100
                10100 10100 10100 10100 10100 10100 10100 10100 10100 10100 10100 10100 10100 10100 10100 10100 10100 10100
                10000 10000 10000>;

            PS_Config_Lmt_Open_Rawdata_P = <
                65535 2376 2351 2233 2198 2143 2027 1982 1917 1980 2054 2104 2211 2243 2264 2373 2404 65535
                2446 2439 2425 2352 2290 2257 2219 2184 2166 2250 2281 2313 2348 2373 2411 2464 2471 2390
                2503 2488 2471 2405 2349 2317 2281 2247 2229 2313 2338 2379 2409 2435 2475 2521 2538 2465
                2538 2514 2512 2425 2369 2344 2303 2268 2250 2295 2318 2360 2394 2409 2449 2510 2512 2453
                2594 2575 2558 2484 2425 2393 2351 2320 2303 2384 2415 2447 2484 2505 2544 2594 2615 2569
                2601 2577 2573 2491 2428 2395 2355 2311 2295 2402 2429 2468 2506 2528 2570 2628 2640 2614
                2675 2653 2649 2565 2503 2468 2425 2383 2369 2407 2433 2468 2507 2531 2562 2621 2629 2607
                2743 2712 2703 2619 2559 2519 2474 2436 2418 2416 2444 2477 2523 2547 2582 2646 2657 2649
                2785 2744 2733 2646 2589 2558 2512 2477 2463 2530 2552 2593 2632 2654 2694 2750 2754 2759
                2841 2813 2807 2724 2667 2631 2593 2554 2535 2505 2530 2568 2604 2625 2664 2723 2736 2751
                2908 2874 2869 2786 2727 2688 2643 2605 2582 2579 2604 2646 2687 2715 2757 2814 2825 2856
                2948 2898 2899 2806 2743 2715 2671 2633 2618 2569 2594 2639 2677 2701 2741 2814 2814 2856
                2960 2923 2929 2841 2787 2752 2709 2668 2652 2646 2674 2713 2755 2772 2813 2876 2884 2913
                3020 2979 2964 2890 2828 2789 2744 2710 2689 2677 2708 2741 2785 2804 2845 2906 2912 2957
                3112 3065 3042 2969 2908 2870 2832 2796 2773 2720 2752 2790 2832 2846 2884 2953 2950 2993
                3161 3122 3115 3027 2972 2933 2894 2857 2834 2790 2822 2860 2902 2922 2960 3025 3027 3067
                3186 3143 3132 3048 2989 2951 2908 2870 2839 2866 2895 2934 2975 2999 3042 3104 3107 3144
                3248 3203 3214 3111 3053 3021 2968 2930 2901 2916 2950 2986 3031 3055 3094 3158 3163 3207
                3346 3300 3294 3206 3139 3102 3058 3018 2988 2972 3009 3048 3084 3112 3153 3217 3221 3262
                3371 3329 3315 3228 3163 3122 3080 3042 3007 3025 3065 3104 3142 3171 3212 3279 3277 3324
                3416 3382 3364 3283 3224 3182 3142 3100 3070 3037 3074 3109 3151 3170 3202 3269 3265 3301
                3489 3457 3447 3359 3294 3258 3214 3171 3139 3104 3140 3178 3223 3248 3297 3353 3364 3405
                3497 3476 3471 3384 3322 3289 3240 3200 3171 3122 3156 3198 3231 3261 3303 3360 3363 3406
                3594 3580 3567 3478 3420 3375 3329 3286 3255 3207 3245 3287 3335 3356 3388 3469 3457 3497
                3636 3632 3622 3531 3472 3436 3389 3353 3314 3220 3259 3296 3339 3371 3403 3472 3479 3514
                3731 3732 3725 3633 3576 3531 3485 3441 3402 3300 3338 3374 3426 3455 3497 3564 3573 3611
                3704 3720 3702 3609 3549 3511 3464 3422 3391 3339 3378 3415 3459 3483 3521 3588 3602 3634
                3811 3839 3825 3732 3672 3632 3580 3539 3501 3413 3455 3492 3536 3562 3604 3674 3672 3710
                3870 3903 3891 3807 3749 3707 3660 3620 3580 3458 3501 3541 3587 3619 3657 3721 3724 3762
                3588 3917 3895 3797 3737 3699 3643 3605 3559 3485 3532 3569 3618 3644 3686 3752 3760 3534
                3667 4039 4021 3923 3864 3815 3756 3723 3678 3532 3577 3619 3667 3703 3741 3812 3815 3556
                3879 4064 4078 3987 3921 3871 3822 3788 3744 3588 3630 3665 3707 3742 3784 3857 3844 3772
                5120 5120 5120>;

            PS_Config_Lmt_Open_Rawdata_N = <
                (-65535) 1018 1007 957 942 919 869 850 821 848 880 902 947 961 970 1017 1030 (-65535)
                1048 1045 1039 1008 982 967 951 936 928 964 977 991 1006 1017 1033 1056 1059 1024
                1073 1066 1059 1031 1007 993 977 963 955 991 1002 1019 1033 1043 1061 1081 1088 1057
                1088 1078 1076 1039 1015 1004 987 972 964 983 994 1012 1026 1033 1049 1076 1076 1051
                1112 1103 1096 1064 1039 1025 1007 994 987 1022 1035 1049 1064 1073 1090 1112 1121 1101
                1115 1105 1103 1067 1040 1027 1009 991 983 1030 1041 1058 1074 1084 1102 1126 1132 1120
                1147 1137 1135 1099 1073 1058 1039 1021 1015 1031 1043 1058 1075 1085 1098 1123 1127 1117
                1175 1162 1159 1123 1097 1079 1060 1044 1036 1036 1048 1061 1081 1091 1106 1134 1139 1135
                1193 1176 1171 1134 1109 1096 1076 1061 1055 1084 1094 1111 1128 1138 1154 1178 1180 1183
                1217 1205 1203 1168 1143 1127 1111 1094 1087 1073 1084 1100 1116 1125 1142 1167 1172 1179
                1246 1232 1229 1194 1169 1152 1133 1117 1106 1105 1116 1134 1151 1163 1181 1206 1211 1224
                1264 1242 1243 1202 1175 1163 1145 1129 1122 1101 1112 1131 1147 1157 1175 1206 1206 1224
                1268 1253 1255 1217 1195 1180 1161 1144 1136 1134 1146 1163 1181 1188 1205 1232 1236 1249
                1294 1277 1270 1238 1212 1195 1176 1162 1153 1147 1160 1175 1193 1202 1219 1246 1248 1267
                1334 1313 1304 1273 1246 1230 1214 1198 1189 1166 1180 1196 1214 1220 1236 1265 1264 1283
                1355 1338 1335 1297 1274 1257 1240 1225 1214 1196 1210 1226 1244 1252 1268 1297 1297 1315
                1366 1347 1342 1306 1281 1265 1246 1230 1217 1228 1241 1258 1275 1285 1304 1330 1331 1348
                1392 1373 1378 1333 1309 1295 1272 1256 1243 1250 1264 1280 1299 1309 1326 1354 1355 1375
                1434 1414 1412 1374 1345 1330 1310 1294 1280 1274 1289 1306 1322 1334 1351 1379 1381 1398
                1445 1427 1421 1384 1355 1338 1320 1304 1289 1297 1313 1330 1346 1359 1376 1405 1405 1424
                1464 1450 1442 1407 1382 1364 1346 1328 1316 1301 1318 1333 1351 1358 1372 1401 1399 1415
                1495 1481 1477 1439 1412 1396 1378 1359 1345 1330 1346 1362 1381 1392 1413 1437 1442 1459
                1499 1490 1487 1450 1424 1409 1388 1372 1359 1338 1352 1370 1385 1397 1415 1440 1441 1460
                1540 1534 1529 1490 1466 1447 1427 1408 1395 1375 1391 1409 1429 1438 1452 1487 1481 1499
                1558 1556 1552 1513 1488 1472 1453 1437 1420 1380 1397 1412 1431 1445 1459 1488 1491 1506
                1599 1600 1597 1557 1532 1513 1493 1475 1458 1414 1430 1446 1468 1481 1499 1528 1531 1547
                1588 1594 1586 1547 1521 1505 1484 1466 1453 1431 1448 1463 1483 1493 1509 1538 1544 1558
                1633 1645 1639 1600 1574 1556 1534 1517 1501 1463 1481 1496 1516 1526 1544 1574 1574 1590
                1658 1673 1667 1631 1607 1589 1568 1552 1534 1482 1501 1517 1537 1551 1567 1595 1596 1612
                1538 1679 1669 1627 1601 1585 1561 1545 1525 1493 1514 1529 1550 1562 1580 1608 1612 1514
                1571 1731 1723 1681 1656 1635 1610 1595 1576 1514 1533 1551 1571 1587 1603 1634 1635 1524
                1663 1742 1748 1709 1681 1659 1638 1624 1604 1538 1556 1571 1589 1604 1622 1653 1648 1616
                (-511) (-511) (-511)>;

            PS_Config_Lmt_FW_Rawdata_P = <
                65535 1119 1137 1128 1126 1135 1119 1119 1124 1134 1105 1109 1105 1121 1107 1107 1106 65535
                1123 1130 1103 1140 1165 1154 1168 1135 1105 1120 1117 1120 1126 1131 1121 1114 1141 1105
                1105 1099 1110 1142 1133 1124 1131 1119 1119 1123 1109 1114 1116 1119 1117 1120 1127 1135
                1124 1121 1137 1106 1107 1105 1105 1130 1147 1131 1123 1119 1119 1110 1120 1131 1117 1128
                1112 1133 1144 1116 1112 1117 1126 1135 1117 1105 1112 1119 1124 1116 1121 1103 1116 1095
                1119 1105 1144 1099 1098 1110 1110 1135 1127 1135 1121 1110 1112 1109 1110 1120 1120 1091
                1142 1137 1140 1099 1099 1103 1114 1128 1116 1119 1128 1121 1120 1127 1127 1119 1114 1128
                1114 1124 1121 1109 1110 1114 1110 1121 1120 1133 1093 1079 1084 1079 1085 1084 1140 1099
                1141 1140 1117 1121 1124 1127 1134 1102 1128 1119 1092 1112 1110 1103 1095 1100 1112 1112
                1105 1078 1135 1140 1135 1133 1137 1142 1079 1099 1126 1124 1117 1116 1110 1126 1113 1085
                1092 1112 1123 1137 1131 1128 1126 1119 1124 1110 1151 1141 1137 1134 1126 1135 1096 1093
                1107 1110 1120 1119 1121 1116 1121 1113 1127 1114 1130 1123 1127 1126 1123 1123 1147 1096
                1123 1135 1106 1117 1116 1121 1112 1106 1119 1124 1116 1113 1117 1117 1112 1102 1137 1144
                1126 1126 1149 1135 1135 1137 1130 1133 1085 1079 1151 1152 1147 1151 1151 1142 1078 1099
                1107 1105 1140 1140 1117 1135 1141 1126 1131 1134 1107 1109 1105 1092 1100 1089 1141 1131
                1088 1114 1114 1135 1131 1138 1141 1137 1091 1123 1135 1133 1138 1137 1135 1134 1100 1105
                1133 1144 1100 1119 1112 1116 1106 1109 1127 1134 1091 1091 1106 1100 1116 1112 1130 1124
                1140 1127 1112 1116 1095 1100 1100 1081 1142 1116 1131 1123 1134 1116 1117 1134 1091 1142
                1117 1092 1147 1123 1135 1141 1135 1142 1098 1089 1149 1134 1137 1135 1149 1154 1089 1112
                1126 1112 1140 1126 1124 1117 1109 1117 1128 1130 1089 1088 1088 1099 1107 1127 1107 1121
                1151 1126 1103 1113 1109 1109 1110 1121 1109 1131 1100 1092 1109 1103 1095 1089 1130 1169
                1119 1124 1100 1128 1124 1124 1121 1130 1072 1100 1130 1124 1134 1126 1114 1140 1110 1140
                1161 1133 1077 1081 1063 1058 1065 1061 1165 1137 1093 1100 1098 1093 1070 1135 1107 1144
                1127 1117 1116 1127 1140 1137 1133 1126 1119 1137 1113 1112 1112 1113 1081 1140 1109 1134
                1120 1128 1092 1099 1098 1103 1100 1106 1113 1140 1116 1114 1095 1086 1105 1100 1135 1176
                1100 1078 1133 1134 1138 1135 1130 1120 1109 1123 1107 1109 1110 1100 1103 1114 1099 1147
                1116 1095 1137 1113 1109 1135 1137 1147 1110 1064 1137 1138 1145 1151 1142 1126 1127 1092
                1121 1141 1105 1119 1119 1119 1112 1113 1106 1130 1110 1112 1092 1086 1093 1103 1120 1114
                1124 1109 1112 1114 1123 1126 1121 1120 1117 1112 1103 1112 1107 1110 1096 1131 1099 1137
                1119 1120 1119 1110 1119 1109 1103 1102 1124 1100 1130 1137 1120 1113 1106 1120 1109 1102
                1102 1107 1149 1089 1121 1110 1130 1123 1130 1127 1110 1116 1116 1116 1126 1109 1107 1121
                1117 1096 1134 1091 1085 1085 1075 1099 1141 1110 1117 1120 1113 1116 1120 1098 1116 1120
                3840 3840 3840>;

            PS_Config_Lmt_FW_Rawdata_N = <
                (-65535) 479 487 484 482 487 479 479 482 486 473 475 473 481 475 475 474 (-65535)
                481 484 473 488 499 494 500 487 473 480 479 480 482 485 481 478 489 473
                473 471 476 490 485 482 485 479 479 481 475 478 478 479 479 480 483 487
                482 481 487 474 475 473 473 484 491 485 481 479 479 476 480 485 479 484
                476 485 490 478 476 479 482 487 479 473 476 479 482 478 481 473 478 469
                479 473 490 471 470 476 476 487 483 487 481 476 476 475 476 480 480 467
                490 487 488 471 471 473 478 484 478 479 484 481 480 483 483 479 478 484
                478 482 481 475 476 478 476 481 480 485 469 463 464 463 465 464 488 471
                489 488 479 481 482 483 486 472 484 479 468 476 476 473 469 472 476 476
                473 462 487 488 487 485 487 490 463 471 482 482 479 478 476 482 477 465
                468 476 481 487 485 484 482 479 482 476 493 489 487 486 482 487 470 469
                475 476 480 479 481 478 481 477 483 478 484 481 483 482 481 481 491 470
                481 487 474 479 478 481 476 474 479 482 478 477 479 479 476 472 487 490
                482 482 493 487 487 487 484 485 465 463 493 494 491 493 493 490 462 471
                475 473 488 488 479 487 489 482 485 486 475 475 473 468 472 467 489 485
                466 478 478 487 485 488 489 487 467 481 487 485 488 487 487 486 472 473
                485 490 472 479 476 478 474 475 483 486 467 467 474 472 478 476 484 482
                488 483 476 478 469 472 472 463 490 478 485 481 486 478 479 486 467 490
                479 468 491 481 487 489 487 490 470 467 493 486 487 487 493 494 467 476
                482 476 488 482 482 479 475 479 484 484 467 466 466 471 475 483 475 481
                493 482 473 477 475 475 476 481 475 485 472 468 475 473 469 467 484 501
                479 482 472 484 482 482 481 484 460 472 484 482 486 482 478 488 476 488
                497 485 461 463 455 454 457 455 499 487 469 472 470 469 458 487 475 490
                483 479 478 483 488 487 485 482 479 487 477 476 476 477 463 488 475 486
                480 484 468 471 470 473 472 474 477 488 478 478 469 466 473 472 487 504
                472 462 485 486 488 487 484 480 475 481 475 475 476 472 473 478 471 491
                478 469 487 477 475 487 487 491 476 456 487 488 491 493 490 482 483 468
                481 489 473 479 479 479 476 477 474 484 476 476 468 466 469 473 480 478
                482 475 476 478 481 482 481 480 479 476 473 476 475 476 470 485 471 487
                479 480 479 476 479 475 473 472 482 472 484 487 480 477 474 480 475 472
                472 475 493 467 481 476 484 481 484 483 476 478 478 478 482 475 475 481
                479 470 486 467 465 465 461 471 489 476 479 480 477 478 480 470 478 480
                240 240 240>;

            PS_Config_Lmt_FW_CC_P = <
                65535 44 43 39 39 37 36 36 36 36 36 36 37 37 39 43 44 65535
                50 48 46 44 44 44 44 44 44 44 44 44 44 44 44 46 47 50
                51 48 47 44 44 44 44 44 46 46 44 44 44 44 44 47 48 50
                51 48 46 44 44 44 44 44 46 46 46 44 44 44 44 47 48 50
                51 48 47 44 44 44 44 46 46 46 46 46 44 46 46 47 48 51
                51 48 46 44 44 44 44 44 46 46 44 44 44 44 44 46 48 50
                51 48 47 46 46 46 46 46 46 46 46 46 46 46 46 47 48 51
                51 48 47 46 46 46 46 46 46 46 46 46 46 46 46 47 48 51
                51 48 47 46 46 46 44 46 46 46 46 46 46 46 46 47 48 51
                51 48 47 44 44 44 44 46 46 46 46 46 46 46 46 47 48 51
                51 48 47 46 46 46 46 46 46 46 46 46 46 46 46 47 48 51
                51 48 47 46 46 46 46 46 46 46 44 44 44 44 44 46 48 51
                51 48 47 46 46 46 46 46 46 46 46 46 46 46 46 47 48 51
                52 48 47 46 46 46 46 46 47 46 46 46 46 46 46 47 48 51
                52 48 47 46 46 46 46 46 46 46 46 46 46 46 46 47 48 51
                52 48 47 46 46 46 46 46 46 46 46 46 46 46 46 47 48 52
                52 48 47 46 46 46 46 46 47 47 46 46 46 46 46 47 50 52
                52 50 47 46 46 46 46 46 47 47 46 46 46 46 46 47 50 52
                52 50 48 47 47 47 47 47 47 47 46 46 46 46 46 47 50 52
                52 50 47 46 46 46 46 46 47 47 47 46 47 46 46 47 50 52
                52 50 47 47 47 47 47 47 47 47 47 47 47 47 47 47 50 52
                54 50 48 47 47 47 47 47 48 48 47 47 47 47 47 48 50 54
                52 50 48 47 47 47 47 47 47 47 47 47 47 47 47 47 50 52
                54 51 48 47 47 47 47 47 48 48 47 47 47 47 47 48 51 54
                54 51 48 47 47 47 47 47 48 47 47 47 47 47 47 48 50 52
                54 51 48 47 47 47 47 47 48 48 47 47 47 47 47 48 51 54
                54 51 50 48 48 48 48 48 48 48 47 47 47 47 47 48 50 54
                54 51 48 48 47 47 47 47 48 48 47 47 47 47 47 48 51 54
                54 51 48 48 48 48 48 48 48 48 47 47 47 47 48 48 51 54
                51 51 48 47 47 47 47 47 48 48 47 47 47 47 47 48 51 52
                52 51 48 48 48 48 48 48 48 48 47 47 47 47 47 48 51 52
                52 51 48 48 48 48 48 47 48 48 47 47 47 47 47 48 51 52
                314 314 314>;

            PS_Config_Lmt_FW_CC_N = <
                (-65535) 20 19 17 17 17 16 16 16 16 16 16 17 17 17 19 20 (-65535)
                22 22 20 20 20 20 20 20 20 20 20 20 20 20 20 20 21 22
                23 22 21 20 20 20 20 20 20 20 20 20 20 20 20 21 22 22
                23 22 20 20 20 20 20 20 20 20 20 20 20 20 20 21 22 22
                23 22 21 20 20 20 20 20 20 20 20 20 20 20 20 21 22 23
                23 22 20 20 20 20 20 20 20 20 20 20 20 20 20 20 22 22
                23 22 21 20 20 20 20 20 20 20 20 20 20 20 20 21 22 23
                23 22 21 20 20 20 20 20 20 20 20 20 20 20 20 21 22 23
                23 22 21 20 20 20 20 20 20 20 20 20 20 20 20 21 22 23
                23 22 21 20 20 20 20 20 20 20 20 20 20 20 20 21 22 23
                23 22 21 20 20 20 20 20 20 20 20 20 20 20 20 21 22 23
                23 22 21 20 20 20 20 20 20 20 20 20 20 20 20 20 22 23
                23 22 21 20 20 20 20 20 20 20 20 20 20 20 20 21 22 23
                24 22 21 20 20 20 20 20 21 20 20 20 20 20 20 21 22 23
                24 22 21 20 20 20 20 20 20 20 20 20 20 20 20 21 22 23
                24 22 21 20 20 20 20 20 20 20 20 20 20 20 20 21 22 24
                24 22 21 20 20 20 20 20 21 21 20 20 20 20 20 21 22 24
                24 22 21 20 20 20 20 20 21 21 20 20 20 20 20 21 22 24
                24 22 22 21 21 21 21 21 21 21 20 20 20 20 20 21 22 24
                24 22 21 20 20 20 20 20 21 21 21 20 21 20 20 21 22 24
                24 22 21 21 21 21 21 21 21 21 21 21 21 21 21 21 22 24
                24 22 22 21 21 21 21 21 22 22 21 21 21 21 21 22 22 24
                24 22 22 21 21 21 21 21 21 21 21 21 21 21 21 21 22 24
                24 23 22 21 21 21 21 21 22 22 21 21 21 21 21 22 23 24
                24 23 22 21 21 21 21 21 22 21 21 21 21 21 21 22 22 24
                24 23 22 21 21 21 21 21 22 22 21 21 21 21 21 22 23 24
                24 23 22 22 22 22 22 22 22 22 21 21 21 21 21 22 22 24
                24 23 22 22 21 21 21 21 22 22 21 21 21 21 21 22 23 24
                24 23 22 22 22 22 22 22 22 22 21 21 21 21 22 22 23 24
                23 23 22 21 21 21 21 21 22 22 21 21 21 21 21 22 23 24
                24 23 22 22 22 22 22 22 22 22 21 21 21 21 21 22 23 24
                24 23 22 22 22 22 22 21 22 22 21 21 21 21 21 22 23 24
                0 0 0>;

            PS_Config_Lmt_FW_Diff_P = <
                65535 50 50 50 50 50 50 50 50 50 50 50 50 50 50 50 50 65535
                50 50 50 50 50 50 50 50 50 50 50 50 50 50 50 50 50 50
                50 50 50 50 50 50 50 50 50 50 50 50 50 50 50 50 50 50
                50 50 50 50 50 50 50 50 50 50 50 50 50 50 50 50 50 50
                50 50 50 50 50 50 50 50 50 50 50 50 50 50 50 50 50 50
                50 50 50 50 50 50 50 50 50 50 50 50 50 50 50 50 50 50
                50 50 50 50 50 50 50 50 50 50 50 50 50 50 50 50 50 50
                50 50 50 50 50 50 50 50 50 50 50 50 50 50 50 50 50 50
                50 50 50 50 50 50 50 50 50 50 50 50 50 50 50 50 50 50
                50 50 50 50 50 50 50 50 50 50 50 50 50 50 50 50 50 50
                50 50 50 50 50 50 50 50 50 50 50 50 50 50 50 50 50 50
                50 50 50 50 50 50 50 50 50 50 50 50 50 50 50 50 50 50
                50 50 50 50 50 50 50 50 50 50 50 50 50 50 50 50 50 50
                50 50 50 50 50 50 50 50 50 50 50 50 50 50 50 50 50 50
                50 50 50 50 50 50 50 50 50 50 50 50 50 50 50 50 50 50
                50 50 50 50 50 50 50 50 50 50 50 50 50 50 50 50 50 50
                50 50 50 50 50 50 50 50 50 50 50 50 50 50 50 50 50 50
                50 50 50 50 50 50 50 50 50 50 50 50 50 50 50 50 50 50
                50 50 50 50 50 50 50 50 50 50 50 50 50 50 50 50 50 50
                50 50 50 50 50 50 50 50 50 50 50 50 50 50 50 50 50 50
                50 50 50 50 50 50 50 50 50 50 50 50 50 50 50 50 50 50
                50 50 50 50 50 50 50 50 50 50 50 50 50 50 50 50 50 50
                50 50 50 50 50 50 50 50 50 50 50 50 50 50 50 50 50 50
                50 50 50 50 50 50 50 50 50 50 50 50 50 50 50 50 50 50
                50 50 50 50 50 50 50 50 50 50 50 50 50 50 50 50 50 50
                50 50 50 50 50 50 50 50 50 50 50 50 50 50 50 50 50 50
                50 50 50 50 50 50 50 50 50 50 50 50 50 50 50 50 50 50
                50 50 50 50 50 50 50 50 50 50 50 50 50 50 50 50 50 50
                50 50 50 50 50 50 50 50 50 50 50 50 50 50 50 50 50 50
                50 50 50 50 50 50 50 50 50 50 50 50 50 50 50 50 50 50
                50 50 50 50 50 50 50 50 50 50 50 50 50 50 50 50 50 50
                50 50 50 50 50 50 50 50 50 50 50 50 50 50 50 50 50 50
                75 75 75>;

            PS_Config_Lmt_FW_Diff_N = <
                (-65535) (-50) (-50) (-50) (-50) (-50) (-50) (-50) (-50) (-50) (-50) (-50) (-50) (-50) (-50) (-50) (-50) (-65535)
                (-50) (-50) (-50) (-50) (-50) (-50) (-50) (-50) (-50) (-50) (-50) (-50) (-50) (-50) (-50) (-50) (-50) (-50)
                (-50) (-50) (-50) (-50) (-50) (-50) (-50) (-50) (-50) (-50) (-50) (-50) (-50) (-50) (-50) (-50) (-50) (-50)
                (-50) (-50) (-50) (-50) (-50) (-50) (-50) (-50) (-50) (-50) (-50) (-50) (-50) (-50) (-50) (-50) (-50) (-50)
                (-50) (-50) (-50) (-50) (-50) (-50) (-50) (-50) (-50) (-50) (-50) (-50) (-50) (-50) (-50) (-50) (-50) (-50)
                (-50) (-50) (-50) (-50) (-50) (-50) (-50) (-50) (-50) (-50) (-50) (-50) (-50) (-50) (-50) (-50) (-50) (-50)
                (-50) (-50) (-50) (-50) (-50) (-50) (-50) (-50) (-50) (-50) (-50) (-50) (-50) (-50) (-50) (-50) (-50) (-50)
                (-50) (-50) (-50) (-50) (-50) (-50) (-50) (-50) (-50) (-50) (-50) (-50) (-50) (-50) (-50) (-50) (-50) (-50)
                (-50) (-50) (-50) (-50) (-50) (-50) (-50) (-50) (-50) (-50) (-50) (-50) (-50) (-50) (-50) (-50) (-50) (-50)
                (-50) (-50) (-50) (-50) (-50) (-50) (-50) (-50) (-50) (-50) (-50) (-50) (-50) (-50) (-50) (-50) (-50) (-50)
                (-50) (-50) (-50) (-50) (-50) (-50) (-50) (-50) (-50) (-50) (-50) (-50) (-50) (-50) (-50) (-50) (-50) (-50)
                (-50) (-50) (-50) (-50) (-50) (-50) (-50) (-50) (-50) (-50) (-50) (-50) (-50) (-50) (-50) (-50) (-50) (-50)
                (-50) (-50) (-50) (-50) (-50) (-50) (-50) (-50) (-50) (-50) (-50) (-50) (-50) (-50) (-50) (-50) (-50) (-50)
                (-50) (-50) (-50) (-50) (-50) (-50) (-50) (-50) (-50) (-50) (-50) (-50) (-50) (-50) (-50) (-50) (-50) (-50)
                (-50) (-50) (-50) (-50) (-50) (-50) (-50) (-50) (-50) (-50) (-50) (-50) (-50) (-50) (-50) (-50) (-50) (-50)
                (-50) (-50) (-50) (-50) (-50) (-50) (-50) (-50) (-50) (-50) (-50) (-50) (-50) (-50) (-50) (-50) (-50) (-50)
                (-50) (-50) (-50) (-50) (-50) (-50) (-50) (-50) (-50) (-50) (-50) (-50) (-50) (-50) (-50) (-50) (-50) (-50)
                (-50) (-50) (-50) (-50) (-50) (-50) (-50) (-50) (-50) (-50) (-50) (-50) (-50) (-50) (-50) (-50) (-50) (-50)
                (-50) (-50) (-50) (-50) (-50) (-50) (-50) (-50) (-50) (-50) (-50) (-50) (-50) (-50) (-50) (-50) (-50) (-50)
                (-50) (-50) (-50) (-50) (-50) (-50) (-50) (-50) (-50) (-50) (-50) (-50) (-50) (-50) (-50) (-50) (-50) (-50)
                (-50) (-50) (-50) (-50) (-50) (-50) (-50) (-50) (-50) (-50) (-50) (-50) (-50) (-50) (-50) (-50) (-50) (-50)
                (-50) (-50) (-50) (-50) (-50) (-50) (-50) (-50) (-50) (-50) (-50) (-50) (-50) (-50) (-50) (-50) (-50) (-50)
                (-50) (-50) (-50) (-50) (-50) (-50) (-50) (-50) (-50) (-50) (-50) (-50) (-50) (-50) (-50) (-50) (-50) (-50)
                (-50) (-50) (-50) (-50) (-50) (-50) (-50) (-50) (-50) (-50) (-50) (-50) (-50) (-50) (-50) (-50) (-50) (-50)
                (-50) (-50) (-50) (-50) (-50) (-50) (-50) (-50) (-50) (-50) (-50) (-50) (-50) (-50) (-50) (-50) (-50) (-50)
                (-50) (-50) (-50) (-50) (-50) (-50) (-50) (-50) (-50) (-50) (-50) (-50) (-50) (-50) (-50) (-50) (-50) (-50)
                (-50) (-50) (-50) (-50) (-50) (-50) (-50) (-50) (-50) (-50) (-50) (-50) (-50) (-50) (-50) (-50) (-50) (-50)
                (-50) (-50) (-50) (-50) (-50) (-50) (-50) (-50) (-50) (-50) (-50) (-50) (-50) (-50) (-50) (-50) (-50) (-50)
                (-50) (-50) (-50) (-50) (-50) (-50) (-50) (-50) (-50) (-50) (-50) (-50) (-50) (-50) (-50) (-50) (-50) (-50)
                (-50) (-50) (-50) (-50) (-50) (-50) (-50) (-50) (-50) (-50) (-50) (-50) (-50) (-50) (-50) (-50) (-50) (-50)
                (-50) (-50) (-50) (-50) (-50) (-50) (-50) (-50) (-50) (-50) (-50) (-50) (-50) (-50) (-50) (-50) (-50) (-50)
                (-50) (-50) (-50) (-50) (-50) (-50) (-50) (-50) (-50) (-50) (-50) (-50) (-50) (-50) (-50) (-50) (-50) (-50)
                (-75) (-75) (-75)>;

            PS_Config_Diff_Test_Frame = <50>;
        };
    };
};
